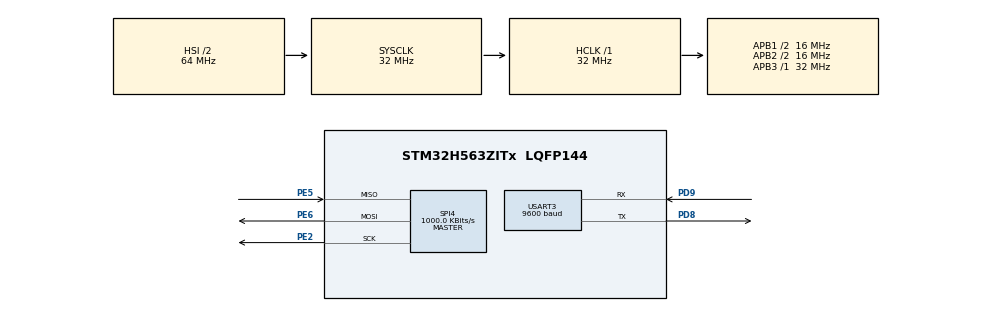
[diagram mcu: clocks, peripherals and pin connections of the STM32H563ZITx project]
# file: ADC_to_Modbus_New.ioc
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CORTEX_M33_NS.Number-Cortex_Memory_Protection_Unit_Region0_OTP_RO_AREAS_Settings=MPU_REGION_NUMBER0
CORTEX_M33_NS.default_mode_Activation=1
CORTEX_M33_NS.userName=CORTEX_M33
Mcu.Family=STM32H5
Mcu.Name=STM32H563ZITx
Mcu.Package=LQFP144
NVIC.PriorityGroup=NVIC_PRIORITYGROUP_4
NVIC.SPI4_IRQn=true\:0\:0\:false\:false\:true\:true\:true\:true
PD8.Mode=Asynchronous
PD8.Signal=USART3_TX
PD9.Mode=Asynchronous
PD9.Signal=USART3_RX
PE2.Mode=Full_Duplex_Master
PE2.Signal=SPI4_SCK
PE5.Mode=Full_Duplex_Master
PE5.Signal=SPI4_MISO
PE6.Mode=Full_Duplex_Master
PE6.Signal=SPI4_MOSI
PH0-OSC_IN(PH0).Mode=HSE-External-Oscillator
PH0-OSC_IN(PH0).Signal=RCC_OSC_IN
PH1-OSC_OUT(PH1).Mode=HSE-External-Oscillator
PH1-OSC_OUT(PH1).Signal=RCC_OSC_OUT
ProjectManager.HeapSize=0x200
ProjectManager.StackSize=0x400
ProjectManager.TargetToolchain=Makefile
RCC.ADCFreq_Value=32000000
RCC.AHBFreq_Value=32000000
RCC.APB1CLKDivider=RCC_HCLK_DIV2
RCC.APB1Freq_Value=16000000
RCC.APB1TimFreq_Value=32000000
RCC.APB2CLKDivider=RCC_HCLK_DIV2
RCC.APB2Freq_Value=16000000
RCC.APB2TimFreq_Value=32000000
RCC.APB3Freq_Value=32000000
RCC.CSI_VALUE=4000000
RCC.CortexFreq_Value=32000000
RCC.EPOD_VALUE=25000000
RCC.HCLKFreq_Value=32000000
RCC.HSE_VALUE=25000000
RCC.HSI48_VALUE=48000000
RCC.HSI_VALUE=64000000
RCC.LSE_VALUE=32768
RCC.LSIRC_VALUE=32000
RCC.PLLFRACN=0
RCC.PLLM=2
RCC.PLLN=40
RCC.PLLSourceVirtual=RCC_PLL1_SOURCE_HSE
RCC.SYSCLKFreq_VALUE=32000000
RCC.USBFreq_Value=48000000
RCC.VCOOutputFreq_Value=500000000
SPI4.BaudRatePrescaler=SPI_BAUDRATEPRESCALER_16
SPI4.CLKPhase=SPI_PHASE_2EDGE
SPI4.CLKPolarity=SPI_POLARITY_LOW
SPI4.CRCCalculation=SPI_CRCCALCULATION_DISABLE
SPI4.CalculateBaudRate=1000.0 KBits/s
SPI4.DataSize=SPI_DATASIZE_16BIT
SPI4.Direction=SPI_DIRECTION_2LINES
SPI4.FifoThreshold=SPI_FIFO_THRESHOLD_08DATA
SPI4.Mode=SPI_MODE_MASTER
SPI4.VirtualType=VM_MASTER
USART3.BaudRate=9600
USART3.RxPinLevelInvertParam=ADVFEATURE_RXINV_DISABLE
USART3.SwapParam=ADVFEATURE_SWAP_DISABLE
USART3.TxPinLevelInvertParam=ADVFEATURE_TXINV_DISABLE
USART3.VirtualMode-Asynchronous=VM_ASYNC
VP_BOOTPATH_VS_BOOTPATH.Mode=BP_Activate
VP_CORTEX_M33_NS_VS_Hclk.Mode=Hclk_Mode
VP_CRC_VS_CRC.Mode=CRC_Activate
VP_ICACHE_VS_ICACHE.Mode=DirectMappedCache
VP_MEMORYMAP_VS_MEMORYMAP.Mode=CurAppReg
VP_PWR_VS_LPOM.Mode=PowerOptimisation
VP_PWR_VS_SECSignals.Mode=Security/Privilege
board=custom

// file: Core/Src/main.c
/* USER CODE BEGIN Header */
/**
  ******************************************************************************
  * @file           : main.c
  * @brief          : Main program body
  ******************************************************************************
  * @attention
  *
  * Copyright (c) 2026 STMicroelectronics.
  * All rights reserved.
  *
  * This software is licensed under terms that can be found in the LICENSE file
  * in the root directory of this software component.
  * If no LICENSE file comes with this software, it is provided AS-IS.
  *
  ******************************************************************************
  */
/* USER CODE END Header */
#include "main.h"
#include "stm32h5xx_hal_spi.h"
#include "stm32h5xx_hal_uart.h"
#include "stm32h5xx_hal.h"   // HAL functions
#include "stdint.h"          // for uint8_t, uint16_t
#include "stm32h5xx_hal.h"
#include "stm32h5xx_hal_gpio.h"
#include "modbus.h"
#include <stdio.h>
#include <string.h>

/* USER CODE BEGIN PTD */
extern UART_HandleTypeDef huart3;

// Retarget printf to UART3
int fputc(int ch, FILE *f) {
    HAL_UART_Transmit(&huart3, (uint8_t *)&ch, 1, HAL_MAX_DELAY);
    return ch;
}
/* USER CODE END PTD */

CRC_HandleTypeDef hcrc;

SPI_HandleTypeDef hspi4;

UART_HandleTypeDef huart3;

void SystemClock_Config(void);
static void MPU_Config(void);
static void MX_GPIO_Init(void);
static void MX_CRC_Init(void);
static void MX_ICACHE_Init(void);
static void MX_SPI4_Init(void);
static void MX_USART3_UART_Init(void);

int main(void)
{

  /* MCU Configuration--------------------------------------------------------*/

  /* MPU Configuration--------------------------------------------------------*/
  MPU_Config();

  /* Reset of all peripherals, Initializes the Flash interface and the Systick. */
  HAL_Init();

  /* Configure the system clock */
  SystemClock_Config();

  /* Initialize all configured peripherals */
  MX_GPIO_Init();
  MX_CRC_Init();
  MX_ICACHE_Init();
  MX_SPI4_Init();
  MX_USART3_UART_Init();

  /* Infinite loop */
  /* USER CODE BEGIN WHILE */
  while (1)
  {

    // // Dummy ADC value for testing
    // uint16_t adc_value = 1234;
    // uint8_t adc_data[2];
    // adc_data[0] = (adc_value >> 8) & 0xFF; // High byte
    // adc_data[1] = adc_value & 0xFF;        // Low byte

    // // Send Modbus response (Slave ID=1, Function=0x03)
    // Modbus_SendResponse(1, 0x03, adc_data, 2);

    // Debug print
   // printf("Sent ADC value: %d\r\n", adc_value);

    printf("Hello UART3\r\n");
    HAL_Delay(1000);

  }
  /* USER CODE END 3 */
}

void SystemClock_Config(void)
{
  RCC_OscInitTypeDef RCC_OscInitStruct = {0};
  RCC_ClkInitTypeDef RCC_ClkInitStruct = {0};

  /** Configure the main internal regulator output voltage
  */
  __HAL_PWR_VOLTAGESCALING_CONFIG(PWR_REGULATOR_VOLTAGE_SCALE3);

  while(!__HAL_PWR_GET_FLAG(PWR_FLAG_VOSRDY)) {}

  /** Initializes the RCC Oscillators according to the specified parameters
  * in the RCC_OscInitTypeDef structure.
  */
  RCC_OscInitStruct.OscillatorType = RCC_OSCILLATORTYPE_HSI;
  RCC_OscInitStruct.HSIState = RCC_HSI_ON;
  RCC_OscInitStruct.HSIDiv = RCC_HSI_DIV2;
  RCC_OscInitStruct.HSICalibrationValue = RCC_HSICALIBRATION_DEFAULT;
  RCC_OscInitStruct.PLL.PLLState = RCC_PLL_NONE;
  if (HAL_RCC_OscConfig(&RCC_OscInitStruct) != HAL_OK)
  {
    Error_Handler();
  }

  /** Initializes the CPU, AHB and APB buses clocks
  */
  RCC_ClkInitStruct.ClockType = RCC_CLOCKTYPE_HCLK|RCC_CLOCKTYPE_SYSCLK
                              |RCC_CLOCKTYPE_PCLK1|RCC_CLOCKTYPE_PCLK2
                              |RCC_CLOCKTYPE_PCLK3;
  RCC_ClkInitStruct.SYSCLKSource = RCC_SYSCLKSOURCE_HSI;
  RCC_ClkInitStruct.AHBCLKDivider = RCC_SYSCLK_DIV1;
  RCC_ClkInitStruct.APB1CLKDivider = RCC_HCLK_DIV2;
  RCC_ClkInitStruct.APB2CLKDivider = RCC_HCLK_DIV2;
  RCC_ClkInitStruct.APB3CLKDivider = RCC_HCLK_DIV1;

  if (HAL_RCC_ClockConfig(&RCC_ClkInitStruct, FLASH_LATENCY_1) != HAL_OK)
  {
    Error_Handler();
  }

  /** Configure the programming delay
  */
  __HAL_FLASH_SET_PROGRAM_DELAY(FLASH_PROGRAMMING_DELAY_0);
}

static void MX_CRC_Init(void)
{

  hcrc.Instance = CRC;
  hcrc.Init.DefaultPolynomialUse = DEFAULT_POLYNOMIAL_ENABLE;
  hcrc.Init.DefaultInitValueUse = DEFAULT_INIT_VALUE_ENABLE;
  hcrc.Init.InputDataInversionMode = CRC_INPUTDATA_INVERSION_NONE;
  hcrc.Init.OutputDataInversionMode = CRC_OUTPUTDATA_INVERSION_DISABLE;
  hcrc.InputDataFormat = CRC_INPUTDATA_FORMAT_BYTES;
  if (HAL_CRC_Init(&hcrc) != HAL_OK)
  {
    Error_Handler();
  }

}

static void MX_ICACHE_Init(void)
{

  /** Enable instruction cache in 1-way (direct mapped cache)
  */
  if (HAL_ICACHE_ConfigAssociativityMode(ICACHE_1WAY) != HAL_OK)
  {
    Error_Handler();
  }
  if (HAL_ICACHE_Enable() != HAL_OK)
  {
    Error_Handler();
  }

}

static void MX_SPI4_Init(void)
{

  /* SPI4 parameter configuration*/
  hspi4.Instance = SPI4;
  hspi4.Init.Mode = SPI_MODE_MASTER;
  hspi4.Init.Direction = SPI_DIRECTION_2LINES;
  hspi4.Init.DataSize = SPI_DATASIZE_16BIT;
  hspi4.Init.CLKPolarity = SPI_POLARITY_LOW;
  hspi4.Init.CLKPhase = SPI_PHASE_2EDGE;
  hspi4.Init.NSS = SPI_NSS_SOFT;
  hspi4.Init.BaudRatePrescaler = SPI_BAUDRATEPRESCALER_16;
  hspi4.Init.FirstBit = SPI_FIRSTBIT_MSB;
  hspi4.Init.TIMode = SPI_TIMODE_DISABLE;
  hspi4.Init.CRCCalculation = SPI_CRCCALCULATION_DISABLE;
  hspi4.Init.CRCPolynomial = 0x7;
  hspi4.Init.NSSPMode = SPI_NSS_PULSE_DISABLE;
  hspi4.Init.NSSPolarity = SPI_NSS_POLARITY_LOW;
  hspi4.Init.FifoThreshold = SPI_FIFO_THRESHOLD_08DATA;
  hspi4.Init.MasterSSIdleness = SPI_MASTER_SS_IDLENESS_00CYCLE;
  hspi4.Init.MasterInterDataIdleness = SPI_MASTER_INTERDATA_IDLENESS_00CYCLE;
  hspi4.Init.MasterReceiverAutoSusp = SPI_MASTER_RX_AUTOSUSP_DISABLE;
  hspi4.Init.MasterKeepIOState = SPI_MASTER_KEEP_IO_STATE_DISABLE;
  hspi4.Init.IOSwap = SPI_IO_SWAP_DISABLE;
  hspi4.Init.ReadyMasterManagement = SPI_RDY_MASTER_MANAGEMENT_INTERNALLY;
  hspi4.Init.ReadyPolarity = SPI_RDY_POLARITY_HIGH;
  if (HAL_SPI_Init(&hspi4) != HAL_OK)
  {
    Error_Handler();
  }

}

static void MX_USART3_UART_Init(void)
{

  huart3.Instance = USART3;
  huart3.Init.BaudRate = 9600;
  huart3.Init.WordLength = UART_WORDLENGTH_8B;
  huart3.Init.StopBits = UART_STOPBITS_1;
  huart3.Init.Parity = UART_PARITY_NONE;
  huart3.Init.Mode = UART_MODE_TX_RX;
  huart3.Init.HwFlowCtl = UART_HWCONTROL_NONE;
  huart3.Init.OverSampling = UART_OVERSAMPLING_16;
  huart3.Init.OneBitSampling = UART_ONE_BIT_SAMPLE_DISABLE;
  huart3.Init.ClockPrescaler = UART_PRESCALER_DIV1;
  huart3.AdvancedInit.AdvFeatureInit = UART_ADVFEATURE_NO_INIT;
  if (HAL_UART_Init(&huart3) != HAL_OK)
  {
    Error_Handler();
  }
  if (HAL_UARTEx_SetTxFifoThreshold(&huart3, UART_TXFIFO_THRESHOLD_1_8) != HAL_OK)
  {
    Error_Handler();
  }
  if (HAL_UARTEx_SetRxFifoThreshold(&huart3, UART_RXFIFO_THRESHOLD_1_8) != HAL_OK)
  {
    Error_Handler();
  }
  if (HAL_UARTEx_DisableFifoMode(&huart3) != HAL_OK)
  {
    Error_Handler();
  }

}

static void MX_GPIO_Init(void)
{

  /* GPIO Ports Clock Enable */
  __HAL_RCC_GPIOE_CLK_ENABLE();
  __HAL_RCC_GPIOH_CLK_ENABLE();
  __HAL_RCC_GPIOD_CLK_ENABLE();

}

 /* MPU Configuration */

void MPU_Config(void)
{
  MPU_Region_InitTypeDef MPU_InitStruct = {0};
  MPU_Attributes_InitTypeDef MPU_AttributesInit = {0};

  /* Disables the MPU */
  HAL_MPU_Disable();

  /** Initializes and configures the Region 0 and the memory to be protected
  */
  MPU_InitStruct.Enable = MPU_REGION_ENABLE;
  MPU_InitStruct.Number = MPU_REGION_NUMBER0;
  MPU_InitStruct.BaseAddress = 0x08FFF000;
  MPU_InitStruct.LimitAddress = 0x08FFFFFF;
  MPU_InitStruct.AttributesIndex = MPU_ATTRIBUTES_NUMBER0;
  MPU_InitStruct.AccessPermission = MPU_REGION_ALL_RO;
  MPU_InitStruct.DisableExec = MPU_INSTRUCTION_ACCESS_DISABLE;
  MPU_InitStruct.IsShareable = MPU_ACCESS_NOT_SHAREABLE;

  HAL_MPU_ConfigRegion(&MPU_InitStruct);

  /** Initializes and configures the Attribute 0 and the memory to be protected
  */
  MPU_AttributesInit.Number = MPU_ATTRIBUTES_NUMBER0;
  MPU_AttributesInit.Attributes = INNER_OUTER(MPU_NOT_CACHEABLE);

  HAL_MPU_ConfigMemoryAttributes(&MPU_AttributesInit);
  /* Enables the MPU */
  HAL_MPU_Enable(MPU_PRIVILEGED_DEFAULT);

}

void Error_Handler(void)
{
  __disable_irq();
  while (1)
  {
  }
}
